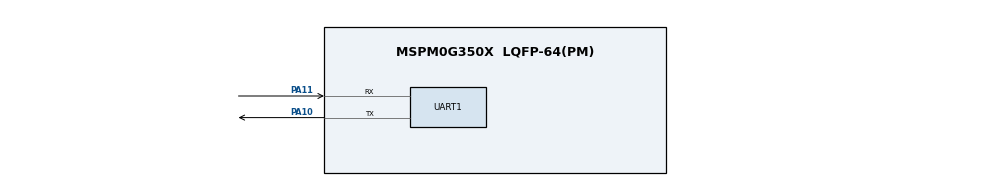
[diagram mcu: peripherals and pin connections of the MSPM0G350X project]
/**
 * @cliArgs --device "MSPM0G350X" --part "Default" --package "LQFP-64(PM)" --product "mspm0_sdk@2.09.00.00"
 * @versions {"tool":"1.26.0+4407"}
 */

/**
 * Import the modules used in this configuration.
 */
const GPIO   = scripting.addModule("/ti/driverlib/GPIO", {}, false);
const GPIO1  = GPIO.addInstance();
const GPIO2  = GPIO.addInstance();
const GPIO3  = GPIO.addInstance();
const GPIO4  = GPIO.addInstance();
const GPIO5  = GPIO.addInstance();
const GPIO6  = GPIO.addInstance();
const SYSCTL = scripting.addModule("/ti/driverlib/SYSCTL");
const UART   = scripting.addModule("/ti/driverlib/UART", {}, false);
const UART1  = UART.addInstance();

/**
 * Write custom configuration values to the imported modules.
 */
GPIO1.$name                                 = "S1_TRIG";
GPIO1.associatedPins[0].$name               = "PIN_0";
GPIO1.associatedPins[0].assignedPortSegment = "Lower";
GPIO1.associatedPins[0].assignedPort        = "PORTB";
GPIO1.associatedPins[0].assignedPin         = "4";

const Board = scripting.addModule("/ti/driverlib/Board", {}, false);

GPIO2.$name                          = "S1_ECHO";
GPIO2.associatedPins[0].$name        = "PIN_1";
GPIO2.associatedPins[0].direction    = "INPUT";
GPIO2.associatedPins[0].assignedPort = "PORTB";
GPIO2.associatedPins[0].assignedPin  = "1";

GPIO3.$name                                 = "S2_TRIG";
GPIO3.associatedPins[0].$name               = "PIN_2";
GPIO3.associatedPins[0].assignedPortSegment = "Upper";
GPIO3.associatedPins[0].assignedPin         = "20";
GPIO3.associatedPins[0].assignedPort        = "PORTB";

GPIO4.$name                                 = "S2_ECHO";
GPIO4.associatedPins[0].$name               = "PIN_3";
GPIO4.associatedPins[0].direction           = "INPUT";
GPIO4.associatedPins[0].assignedPin         = "13";
GPIO4.associatedPins[0].assignedPortSegment = "Lower";
GPIO4.associatedPins[0].assignedPort        = "PORTB";

GPIO5.$name                                 = "S3_TRIG";
GPIO5.associatedPins[0].$name               = "PIN_4";
GPIO5.associatedPins[0].assignedPort        = "PORTB";
GPIO5.associatedPins[0].assignedPortSegment = "Upper";
GPIO5.associatedPins[0].assignedPin         = "17";

GPIO6.$name                                 = "S3_ECHO";
GPIO6.associatedPins[0].$name               = "PIN_5";
GPIO6.associatedPins[0].assignedPort        = "PORTB";
GPIO6.associatedPins[0].assignedPortSegment = "Lower";
GPIO6.associatedPins[0].assignedPin         = "15";
GPIO6.associatedPins[0].direction           = "INPUT";

SYSCTL.forceDefaultClkConfig = true;

UART1.$name                    = "UART_0";
UART1.targetBaudRate           = 115200;
UART1.peripheral.rxPin.$assign = "PA11";
UART1.peripheral.txPin.$assign = "PA10";
UART1.txPinConfig.$name        = "ti_driverlib_gpio_GPIOPinGeneric0";
UART1.rxPinConfig.$name        = "ti_driverlib_gpio_GPIOPinGeneric1";

/**
 * Pinmux solution for unlocked pins/peripherals. This ensures that minor changes to the automatic solver in a future
 * version of the tool will not impact the pinmux you originally saw.  These lines can be completely deleted in order to
 * re-solve from scratch.
 */
GPIO1.associatedPins[0].pin.$suggestSolution = "PB4";
Board.peripheral.$suggestSolution            = "DEBUGSS";
Board.peripheral.swclkPin.$suggestSolution   = "PA20";
Board.peripheral.swdioPin.$suggestSolution   = "PA19";
GPIO2.associatedPins[0].pin.$suggestSolution = "PB1";
GPIO3.associatedPins[0].pin.$suggestSolution = "PB20";
GPIO4.associatedPins[0].pin.$suggestSolution = "PB13";
GPIO5.associatedPins[0].pin.$suggestSolution = "PB17";
GPIO6.associatedPins[0].pin.$suggestSolution = "PB15";
SYSCTL.peripheral.$suggestSolution           = "SYSCTL";
UART1.peripheral.$suggestSolution            = "UART0";
